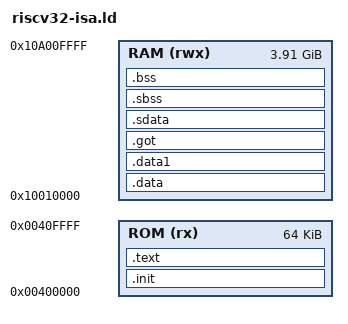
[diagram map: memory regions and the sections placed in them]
OUTPUT_FORMAT("elf32-littleriscv", "elf32-littleriscv",
	      "elf32-littleriscv")
OUTPUT_ARCH(riscv)

MEMORY
{
   /* ISA lab begin */
   ROM (rx)   : ORIGIN = 0x00400000, LENGTH = 64k
   RAM (rwx)  : ORIGIN = 0x10010000, LENGTH = 4000M
   /* ISA lab end */
}

ENTRY(_start)

SECTIONS
{
  /* Read-only sections, merged into text segment: */
  PROVIDE (__executable_start = SEGMENT_START("text-segment", 0x10000)); . = SEGMENT_START("text-segment", 0x10000) + SIZEOF_HEADERS;
  /* ISA lab begin */
  PROVIDE(__stack_top = 0x7fffeffc); 
  /* ISA lab end */
  .init           :
  {
    KEEP (*(SORT_NONE(.init)))
  } > ROM
  .text           :
  {
    *(.text.unlikely .text.*_unlikely .text.unlikely.*)
    *(.text.exit .text.exit.*)
    *(.text.startup .text.startup.*)
    *(.text.hot .text.hot.*)
    *(.text .stub .text.* .gnu.linkonce.t.*)
    /* .gnu.warning sections are handled specially by elf32.em.  */
    *(.gnu.warning)
  } > ROM

  PROVIDE (__etext = .);
  PROVIDE (_etext = .);
  PROVIDE (etext = .);
  .data           :
  {
    *(.data .data.* .gnu.linkonce.d.*)
    SORT(CONSTRUCTORS)
  } > RAM
  .data1          : { *(.data1) } > RAM
  .got            : { *(.got.plt) *(.igot.plt) *(.got) *(.igot) } > RAM
  /* We want the small data sections together, so single-instruction offsets
     can access them all, and initialized data all before uninitialized, so
     we can shorten the on-disk segment size.  */
  .sdata          :
  {
   /* __global_pointer$ = . + 0x800; */
   /* ISA lab begin */
   __global_pointer$ = 0x10008000;
   /* ISA lab end */
    *(.srodata.cst16) *(.srodata.cst8) *(.srodata.cst4) *(.srodata.cst2) *(.srodata .srodata.*)
    *(.sdata .sdata.* .gnu.linkonce.s.*)
  } > RAM
  _edata = .; PROVIDE (edata = .);
  . = .;
  __bss_start = .;
  .sbss           :
  {
    *(.dynsbss)
    *(.sbss .sbss.* .gnu.linkonce.sb.*)
    *(.scommon)
  } > RAM
  .bss            :
  {
   *(.dynbss)
   *(.bss .bss.* .gnu.linkonce.b.*)
   *(COMMON)
   /* Align here to ensure that the .bss section occupies space up to
      _end.  Align after .bss to ensure correct alignment even if the
      .bss section disappears because there are no input sections.
      FIXME: Why do we need it? When there is no .bss section, we don't
      pad the .data section.  */
   . = ALIGN(. != 0 ? 32 / 8 : 1);
  } > RAM
  . = ALIGN(32 / 8);
  . = SEGMENT_START("ldata-segment", .);
  . = ALIGN(32 / 8);
  _end = .; PROVIDE (end = .);
}

